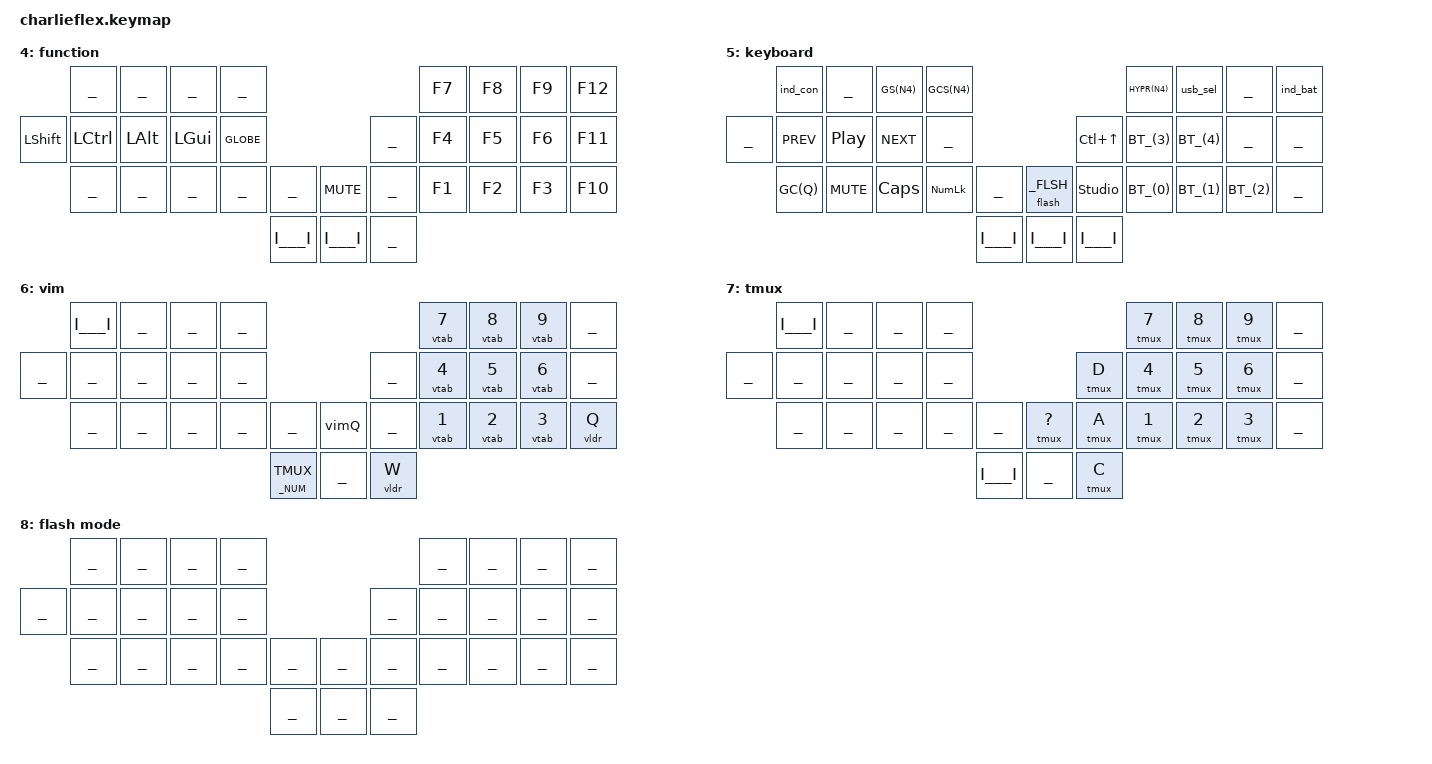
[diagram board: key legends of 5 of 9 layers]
#define ZMK_MOUSE_SCRL_VAL 140

#include <behaviors.dtsi>
#include <dt-bindings/zmk/bt.h>
#include <dt-bindings/zmk/keys.h>
#include <dt-bindings/zmk/outputs.h>
#include <dt-bindings/zmk/pointing.h>
#include <behaviors/rgbled_widget.dtsi>
#include "common.keys"

// Layers
#define _CLMK 0
#define _NUM 1
#define _NAV 2
#define _SYM 3
#define _FN 4
#define _KBD 5
#define _VIM 6
#define _TMUX 7
#define _FLSH 8

// Key positions for combos
// ┏━━━━┳━━━━┳━━━━┳━━━━┓                    ┏━━━━┳━━━━┳━━━━┳━━━━┓
// ┃ 0  ┃ 1  ┃ 2  ┃ 3  ┃                    ┃ 4  ┃ 5  ┃ 6  ┃ 7  ┃
// ┣━━━━╋━━━━╋━━━━╋━━━━╋━━━━┓          ┏━━━━╋━━━━╋━━━━╋━━━━╋━━━━┫
// ┃ 8  ┃ 9  ┃ 10 ┃<11>┃ 12 ┃          ┃ 13 ┃<14>┃ 15 ┃ 16 ┃ 17 ┃
// ┣━━━━╋━━━━╋━━━━╋━━━━╋━━━━┫  ┏━━━━┓  ┣━━━━╋━━━━╋━━━━╋━━━━╋━━━━┫
// ┃ 18 ┃ 19 ┃ 20 ┃ 21 ┃ 22 ┃  ┃ 23 ┃  ┃ 24 ┃ 25 ┃ 26 ┃ 27 ┃ 28 ┃
// ┗━━━━┻━━━━┻━━━━┻━━━━╋━━━━╋━━┻━┳┳━┻━━╋━━━━┻━━━━┻━━━━┻━━━━┻━━━━┛
//                     ┃ 29 ┃ 30 ┃┃ 31 ┃
//                     ┗━━━━┻━━━━┛┗━━━━┛

/ {
    combos {
        compatible = "zmk,combos";

        combo_unlock {
            key-positions = <0 7>;
            bindings = <&studio_unlock>;
            layers = <_CLMK>;
        };

        combo_b {
            key-positions = <3 12>;
            bindings = <&kp B>;
            layers = <_CLMK>;
        };

        combo_j {
            key-positions = <4 13>;
            bindings = <&kp J>;
            layers = <_CLMK>;
        };

        combo_esc {
            key-positions = <1 2 3>;
            bindings = <&kp ESC>;
            layers = <_CLMK>;
        };

        combo_esc_pinky {
            key-positions = <0 1>;
            bindings = <&kp ESC>;
            layers = <_CLMK>;
        };

        combo_backspace {
            key-positions = <4 5 6>;
            bindings = <&kp BSPC>;
            layers = <_CLMK _NUM _NAV>;
        };

        combo_backspace_pinky {
            key-positions = <6 7>;
            bindings = <&kp BSPC>;
            layers = <_CLMK _NUM>;
        };

        combo_tab {
            key-positions = <9 10 11>;
            bindings = <&kp TAB>;
            layers = <_CLMK>;
        };

        combo_tab_pinky {
            key-positions = <18 19>;
            bindings = <&kp TAB>;
            layers = <_CLMK>;
        };

        combo_return {
            key-positions = <14 15 16>;
            bindings = <&kp RET>;
            layers = <_CLMK _NUM _NAV>;
        };

        combo_return_pinky {
            key-positions = <27 28>;
            bindings = <&kp RET>;
            require-prior-idle-ms = <150>;
            layers = <_CLMK _NUM>;
        };

        combo_left_paren {
            key-positions = <2 3>;
            bindings = <&kp LPAR>;
            layers = <_CLMK>;
        };

        combo_right_paren {
            key-positions = <4 5>;
            bindings = <&kp RPAR>;
            require-prior-idle-ms = <150>;
            layers = <_CLMK>;
        };

        combo_left_curly {
            key-positions = <10 11>;
            bindings = <&kp LBRC>;
            require-prior-idle-ms = <150>;
            layers = <_CLMK>;
        };

        combo_right_curly {
            key-positions = <14 15>;
            bindings = <&kp RBRC>;
            require-prior-idle-ms = <150>;
            layers = <_CLMK>;
        };

        combo_left_bracket {
            key-positions = <20 21>;
            bindings = <&kp LBKT>;
            require-prior-idle-ms = <150>;
            layers = <_CLMK>;
        };

        combo_right_bracket {
            key-positions = <25 26>;
            bindings = <&kp RBKT>;
            require-prior-idle-ms = <150>;
            layers = <_CLMK>;
        };

        combo_less_than {
            key-positions = <11 22>;
            bindings = <&kp LT>;
            layers = <_CLMK>;
        };

        combo_greater_than {
            key-positions = <14 24>;
            bindings = <&kp GT>;
            require-prior-idle-ms = <150>;
            layers = <_CLMK>;
        };

        combo_mouse_click {
            key-positions = <12 22>;
            bindings = <&mkp LCLK>;
            layers = <_CLMK>;
        };

        combo_mouse_right_click {
            key-positions = <8 18>;
            bindings = <&mkp RCLK>;
            layers = <_CLMK>;
        };

        combo_mouse_up {
            key-positions = <5 15>;
            bindings = <&mmv MOVE_UP>;
            layers = <_CLMK>;
        };

        combo_mouse_down {
            key-positions = <15 26>;
            bindings = <&mmv MOVE_DOWN>;
            layers = <_CLMK>;
        };

        combo_mouse_left {
            key-positions = <4 14>;
            bindings = <&mmv MOVE_LEFT>;
            layers = <_CLMK>;
        };

        combo_mouse_right {
            key-positions = <6 16>;
            bindings = <&mmv MOVE_RIGHT>;
            layers = <_CLMK>;
        };

        combo_scroll_up {
            key-positions = <2 10>;
            bindings = <&msc SCRL_UP>;
            layers = <_CLMK>;
        };

        combo_scroll_down {
            key-positions = <10 20>;
            bindings = <&msc SCRL_DOWN>;
            layers = <_CLMK>;
        };

        combo_scroll_left {
            key-positions = <1 9>;
            bindings = <&msc SCRL_LEFT>;
            layers = <_CLMK>;
        };

        combo_scroll_right {
            key-positions = <3 11>;
            bindings = <&msc SCRL_RIGHT>;
            layers = <_CLMK>;
        };

        // Combos are always executed on the central, so if we have a dongle
        // without an easily accessible reset button, we can use a combo to
        // put the central into bootloder mode
        combo_flash {
            key-positions = <12 13>;
            bindings = <&flash _FLSH>;
            layers = <_KBD>;
        };
    };

    behaviors {
        hmcs: homerow_mod_comma_semi {
            compatible = "zmk,behavior-hold-tap";
            #binding-cells = <2>;
            tapping-term-ms = <300>;
            require-prior-idle-ms = <150>;
            quick-tap-ms = <0>;
            flavor = "tap-preferred";
            bindings = <&kp>, <&mcs>;
        };

        key_rotation: sensor_rotation_kp {
            compatible = "zmk,behavior-sensor-rotate-var";
            #sensor-binding-cells = <2>;
            bindings = <&kp>, <&kp>;
        };

        scroll_rotation: sensor_rotation_scroll {
            compatible = "zmk,behavior-sensor-rotate-var";
            #sensor-binding-cells = <2>;
            bindings = <&msc>, <&msc>;
            tap-ms = <200>;
        };
    };

    conditional_layers {
        compatible = "zmk,conditional-layers";
        fn_layer {
            if-layers = <_NUM _NAV>;
            then-layer = <_FN>;
        };
        kbd_layer {
            if-layers = <_NAV _SYM>;
            then-layer = <_KBD>;
        };
        tmux_layer {
            if-layers = <_NUM _VIM>;
            then-layer = <_TMUX>;
        };
    };

    keymap {
        compatible = "zmk,keymap";

        colemak {
//                       ┏━━━━━━━━━━━━━━━━━━━━━━━━━┓
            display-name = "Colemak"               ;
//                       ┗━━━━━━━━━━━━━━━━━━━━━━━━━┛
            bindings = <
// ┏━━━━━━━┳━━━━━━━┳━━━━━━━┳━━━━━━━┓                                    ┏━━━━━━━┳━━━━━━━┳━━━━━━━┳━━━━━━━┓
// ┃   Q   ┃   W   ┃   F   ┃   P   ┃                                    ┃   L   ┃   U   ┃   Y   ┃  ' "  ┃
&lt _VIM Q   &kp W   &kp F   &kp P                                        &kp L   &kp U   &kp Y  &kp SQT
// ┣━━━━━━━╋━━━━━━━╋━━━━━━━╋━━━━━━━╋━━━━━━━┓                    ┏━━━━━━━╋━━━━━━━╋━━━━━━━╋━━━━━━━╋━━━━━━━┫
// ┃   A   ┃   R   ┃   S   ┃   T   ┃   G   ┃                    ┃   M   ┃   N   ┃   E   ┃   I   ┃   O   ┃
     Sft A   Ctl R   Opt S   Cmd T   Glb G                        Glb M   Cmd N   Opt E   Ctl I   Sft O
// ┃ Shift ┃ Ctrl  ┃  Opt  ┃  Cmd  ┃ Globe ┃                    ┃ Globe ┃  Cmd  ┃  Opt  ┃ Ctrl  ┃ Shift ┃
// ┣━━━━━━━╋━━━━━━━╋━━━━━━━╋━━━━━━━╋━━━━━━━┫     ┏━━━━━━━━┓     ┣━━━━━━━╋━━━━━━━╋━━━━━━━╋━━━━━━━╋━━━━━━━┫
// ┃   Z   ┃   X   ┃   C   ┃   D   ┃   V   ┃     ┃  MUTE  ┃     ┃   K   ┃   H   ┃  , ;  ┃  . :  ┃  / \  ┃
     &kp Z   &kp X   Alt C   &kp D   &kp V       &kp C_MUTE       &kp K &kp H &hmcs RALT 0 &mdc    &msb
// ┃       ┃       ┃ R Alt ┃       ┃       ┃     ┗━━━━━━━━┛     ┃       ┃       ┃ R Alt ┃       ┃       ┃
// ┗━━━━━━━┻━━━━━━━┻━━━━━━━┻━━━━━━━╋━━━━━━━╋━━━━━━━┓    ┏━━━━━━━╋━━━━━━━┻━━━━━━━┻━━━━━━━┻━━━━━━━┻━━━━━━━┛
//                                 ┃   -   ┃ SHIFT ┃    ┃ SPACE ┃
                          &lt _NUM MINUS &lsscw _NAV 0 &lt _SYM SPC
//                                 ┃  num  ┃  nav  ┃    ┃  sym  ┃
//                                 ┗━━━━━━━┻━━━━━━━┛    ┗━━━━━━━┛
            >;

            sensor-bindings = <&key_rotation C_VOL_UP C_VOL_DN>;
        };

        num {
//                       ┏━━━━━━━━━━━━━━━━━━━━━━━━━┓
            display-name = "numpad"                ;
//                       ┗━━━━━━━━━━━━━━━━━━━━━━━━━┛
            bindings = <
// ┏━━━━━━━┳━━━━━━━┳━━━━━━━┳━━━━━━━┓                                    ┏━━━━━━━┳━━━━━━━┳━━━━━━━┳━━━━━━━┓
// ┃  Esc  ┃       ┃scrnsht┃scrn cp┃                                    ┃   7   ┃   8   ┃   9   ┃   -   ┃
&lt _VIM ESC  ___    GS(N4) GCS(N4)                                    &kp N7  &kp N8  &kp N9  &kp MINUS
// ┣━━━━━━━╋━━━━━━━╋━━━━━━━╋━━━━━━━╋━━━━━━━┓                    ┏━━━━━━━╋━━━━━━━╋━━━━━━━╋━━━━━━━╋━━━━━━━┫
// ┃ CtrlA ┃ Bkspc ┃ SPACE ┃  Tab  ┃ Enter ┃                    ┃   /   ┃   4   ┃   5   ┃   6   ┃   +   ┃
 &kp LC(A) Ctl BSPC Opt SPC Cmd TAB Glb RET                  &kp SLASH &kp N4  &kp N5  &kp N6   &kp PLUS
// ┃       ┃ Ctrl  ┃  Opt  ┃  Cmd  ┃ Globe ┃                    ┃       ┃       ┃       ┃       ┃       ┃
// ┣━━━━━━━╋━━━━━━━╋━━━━━━━╋━━━━━━━╋━━━━━━━┫     ┏━━━━━━━━┓     ┣━━━━━━━╋━━━━━━━╋━━━━━━━╋━━━━━━━╋━━━━━━━┫
// ┃ CtrlZ ┃ CtrlX ┃ CtrlC ┃ CtrlD ┃ CtrlV ┃     ┃  PLAY  ┃     ┃   *   ┃   1   ┃   2   ┃   3   ┃   =   ┃
&kp LC(Z) &kp LC(X) Alt LC(C) &kp LC(D) &kp LC(V) &kp C_PP    &kp STAR &kp N1  &kp N2  &kp N3  &kp EQUAL
// ┃       ┃       ┃ R Alt ┃       ┃       ┃     ┗━━━━━━━━┛     ┃       ┃       ┃       ┃       ┃       ┃
// ┗━━━━━━━┻━━━━━━━┻━━━━━━━┻━━━━━━━╋━━━━━━━╋━━━━━━━┓    ┏━━━━━━━╋━━━━━━━┻━━━━━━━┻━━━━━━━┻━━━━━━━┻━━━━━━━┛
//                                 ┃ ##### ┃       ┃    ┃   0   ┃
                                     I___I &mo _NAV      &kp N0
//                                 ┃  num  ┃ func  ┃    ┃       ┃
//                                 ┗━━━━━━━┻━━━━━━━┛    ┗━━━━━━━┛
            >;

            sensor-bindings = <&key_rotation C_PREV C_NEXT>;
        };

        nav {
//                       ┏━━━━━━━━━━━━━━━━━━━━━━━━━┓
            display-name = "navigation"            ;
//                       ┗━━━━━━━━━━━━━━━━━━━━━━━━━┛
            bindings = <
// ┏━━━━━━━┳━━━━━━━┳━━━━━━━┳━━━━━━━┓                                    ┏━━━━━━━┳━━━━━━━┳━━━━━━━┳━━━━━━━┓
// ┃  Esc  ┃       ┃scrnsht┃scrn cp┃                                    ┃       ┃  Esc  ┃  Del  ┃ Bkspc ┃
    &kp ESC   ___    GS(N4) GCS(N4)                                        ___   &kp ESC &kp DEL &kp BSPC
// ┣━━━━━━━╋━━━━━━━╋━━━━━━━╋━━━━━━━╋━━━━━━━┓                    ┏━━━━━━━╋━━━━━━━╋━━━━━━━╋━━━━━━━╋━━━━━━━┫
// ┃ Cmd A ┃ Bkspc ┃ SPACE ┃  Tab  ┃ Enter ┃                    ┃ Pg Up ┃ Left  ┃  Up   ┃ Right ┃ Enter ┃
 Sft LG(A) Ctl BSPC Opt SPC Cmd TAB Glb RET                    &kp PG_UP &kp LEFT &kp UP &kp RIGHT &kp RET
// ┃ Shift ┃ Ctrl  ┃  Opt  ┃  Cmd  ┃ Globe ┃                    ┃       ┃       ┃       ┃       ┃       ┃
// ┣━━━━━━━╋━━━━━━━╋━━━━━━━╋━━━━━━━╋━━━━━━━┫     ┏━━━━━━━━┓     ┣━━━━━━━╋━━━━━━━╋━━━━━━━╋━━━━━━━╋━━━━━━━┫
// ┃ Cmd Z ┃ Cmd X ┃ Cmd C ┃ Cmd D ┃ Cmd V ┃     ┃  PREV  ┃     ┃ Pg Dn ┃ Home  ┃ Down  ┃  End  ┃ SPACE ┃
&kp LG(Z) &kp LG(X) Alt LG(C) &kp LG(D) &kp LG(V) &kp C_PREV  &kp PG_DN &kp HOME &kp DOWN &kp END &kp SPC
// ┃       ┃       ┃ R Alt ┃       ┃       ┃     ┗━━━━━━━━┛     ┃       ┃       ┃       ┃       ┃       ┃
// ┗━━━━━━━┻━━━━━━━┻━━━━━━━┻━━━━━━━╋━━━━━━━╋━━━━━━━┓    ┏━━━━━━━╋━━━━━━━┻━━━━━━━┻━━━━━━━┻━━━━━━━┻━━━━━━━┛
//                                 ┃       ┃ ##### ┃    ┃  Tab  ┃
                                  &mo _NUM   I___I      &lt _SYM TAB
//                                 ┃ func  ┃       ┃    ┃ keybd ┃
//                                 ┗━━━━━━━┻━━━━━━━┛    ┗━━━━━━━┛
            >;

            sensor-bindings = <&scroll_rotation SCRL_UP SCRL_DOWN>;
        };

        sym {
//                       ┏━━━━━━━━━━━━━━━━━━━━━━━━━┓
            display-name = "symbols"               ;
//                       ┗━━━━━━━━━━━━━━━━━━━━━━━━━┛
            bindings = <
// ┏━━━━━━━┳━━━━━━━┳━━━━━━━┳━━━━━━━┓                                    ┏━━━━━━━┳━━━━━━━┳━━━━━━━┳━━━━━━━┓
// ┃   `   ┃   #   ┃   %   ┃   *   ┃                                    ┃ CtrlL ┃ CtrlU ┃  Del  ┃ Bkspc ┃
&kp GRAVE &kp HASH &kp PRCNT &kp STAR                                 &kp LC(L) &kp LC(U) &kp DEL &kp BSPC
// ┣━━━━━━━╋━━━━━━━╋━━━━━━━╋━━━━━━━╋━━━━━━━┓                    ┏━━━━━━━╋━━━━━━━╋━━━━━━━╋━━━━━━━╋━━━━━━━┫
// ┃   ^   ┃   @   ┃   !   ┃   =   ┃   $   ┃                    ┃ Pg Up ┃ Left  ┃  Up   ┃ Right ┃ Enter ┃
&kp CARET &kp AT &kp EXCL &kp EQUAL &kp DLLR                   Glb PG_UP Cmd LEFT Opt UP Ctl RIGHT &kp RET
// ┃       ┃       ┃       ┃       ┃       ┃                    ┃ Globe ┃  Cmd  ┃  Opt  ┃ Ctrl  ┃       ┃
// ┣━━━━━━━╋━━━━━━━╋━━━━━━━╋━━━━━━━╋━━━━━━━┫     ┏━━━━━━━━┓     ┣━━━━━━━╋━━━━━━━╋━━━━━━━╋━━━━━━━╋━━━━━━━┫
// ┃   ~   ┃   |   ┃   +   ┃   &   ┃   ?   ┃     ┃  NEXT  ┃     ┃ Pg Dn ┃ Home  ┃ Down  ┃  End  ┃ SPACE ┃
&kp TILDE &kp PIPE &kp PLUS &kp AMPS &kp QMARK   &kp C_NEXT   &kp PG_DN &kp HOME Alt DOWN &kp END &kp SPC
// ┃       ┃       ┃       ┃       ┃       ┃     ┗━━━━━━━━┛     ┃       ┃       ┃ R Alt ┃       ┃       ┃
// ┗━━━━━━━┻━━━━━━━┻━━━━━━━┻━━━━━━━╋━━━━━━━╋━━━━━━━┓    ┏━━━━━━━╋━━━━━━━┻━━━━━━━┻━━━━━━━┻━━━━━━━┻━━━━━━━┛
//                                 ┃   _   ┃   /   ┃    ┃ ##### ┃
                               &kp UNDER &lt _NAV SLASH   I___I
//                                 ┃       ┃ keybd ┃    ┃       ┃
//                                 ┗━━━━━━━┻━━━━━━━┛    ┗━━━━━━━┛
            >;

            sensor-bindings = <&scroll_rotation SCRL_UP SCRL_DOWN>;
        };

        fn {
//                       ┏━━━━━━━━━━━━━━━━━━━━━━━━━┓
            display-name = "function"              ;
//                       ┗━━━━━━━━━━━━━━━━━━━━━━━━━┛
            bindings = <
// ┏━━━━━━━┳━━━━━━━┳━━━━━━━┳━━━━━━━┓                                    ┏━━━━━━━┳━━━━━━━┳━━━━━━━┳━━━━━━━┓
// ┃       ┃       ┃       ┃       ┃                                    ┃  F7   ┃  F8   ┃  F9   ┃  F12  ┃
      ___     ___     ___     ___                                        &kp F7  &kp F8  &kp F9  &kp F12
// ┣━━━━━━━╋━━━━━━━╋━━━━━━━╋━━━━━━━╋━━━━━━━┓                    ┏━━━━━━━╋━━━━━━━╋━━━━━━━╋━━━━━━━╋━━━━━━━┫
// ┃       ┃       ┃       ┃       ┃       ┃                    ┃       ┃  F4   ┃  F5   ┃  F6   ┃  F11  ┃
&kp LSHFT &kp LCTRL &kp LALT &kp LGUI &kp GLOBE                    ___   &kp F4  &kp F5  &kp F6  &kp F11
// ┃ Shift ┃ Ctrl  ┃  Opt  ┃  Cmd  ┃ Globe ┃                    ┃       ┃       ┃       ┃       ┃       ┃
// ┣━━━━━━━╋━━━━━━━╋━━━━━━━╋━━━━━━━╋━━━━━━━┫     ┏━━━━━━━━┓     ┣━━━━━━━╋━━━━━━━╋━━━━━━━╋━━━━━━━╋━━━━━━━┫
// ┃       ┃       ┃       ┃       ┃       ┃     ┃  MUTE  ┃     ┃       ┃  F1   ┃  F2   ┃  F3   ┃  F10  ┃
      ___     ___     ___     ___     ___        &kp C_MUTE        ___   &kp F1   &kp F2 &kp F3  &kp F10
// ┃       ┃       ┃       ┃       ┃       ┃     ┗━━━━━━━━┛     ┃       ┃       ┃       ┃       ┃       ┃
// ┗━━━━━━━┻━━━━━━━┻━━━━━━━┻━━━━━━━╋━━━━━━━╋━━━━━━━┓    ┏━━━━━━━╋━━━━━━━┻━━━━━━━┻━━━━━━━┻━━━━━━━┻━━━━━━━┛
//                                 ┃ ##### ┃ ##### ┃    ┃       ┃
                                     I___I   I___I         ___
//                                 ┃       ┃       ┃    ┃       ┃
//                                 ┗━━━━━━━┻━━━━━━━┛    ┗━━━━━━━┛
            >;

            sensor-bindings = <&key_rotation C_BRI_UP C_BRI_DN>;
        };

        kbd {
//                       ┏━━━━━━━━━━━━━━━━━━━━━━━━━┓
            display-name = "keyboard"              ;
//                       ┗━━━━━━━━━━━━━━━━━━━━━━━━━┛
            bindings = <
// ┏━━━━━━━┳━━━━━━━┳━━━━━━━┳━━━━━━━┓                                    ┏━━━━━━━┳━━━━━━━┳━━━━━━━┳━━━━━━━┓
// ┃c stat ┃       ┃scrnsht┃scrn cp┃                                    ┃launchp┃  USB  ┃       ┃battery┃
   &ind_con   ___    GS(N4) GCS(N4)                                     HYPR(N4) &usb_sel  ___  &ind_bat
// ┣━━━━━━━╋━━━━━━━╋━━━━━━━╋━━━━━━━╋━━━━━━━┓                    ┏━━━━━━━╋━━━━━━━╋━━━━━━━╋━━━━━━━╋━━━━━━━┫
// ┃       ┃ prev  ┃ play  ┃ next  ┃       ┃                    ┃mission┃  BT4  ┃  BT5  ┃       ┃       ┃
    ___  &kp C_PREV &kp C_PP &kp C_NEXT  ___                   &kp LC(UP) BT_(3) BT_(4)    ___     ___
// ┃       ┃       ┃       ┃       ┃       ┃                    ┃control┃       ┃       ┃       ┃       ┃
// ┣━━━━━━━╋━━━━━━━╋━━━━━━━╋━━━━━━━╋━━━━━━━┫     ┏━━━━━━━━┓     ┣━━━━━━━╋━━━━━━━╋━━━━━━━╋━━━━━━━╋━━━━━━━┫
// ┃ lock  ┃ mute  ┃caps lk┃numlock┃       ┃     ┃ flash  ┃     ┃studio ┃  BT1  ┃  BT2  ┃  BT3  ┃       ┃
  GC(Q) &kp C_MUTE &kp CAPS &kp KP_NUM  ___   &flash _FLSH &studio_unlock BT_(0)  BT_(1)  BT_(2)   ___
// ┃       ┃       ┃       ┃       ┃       ┃     ┗━━━━━━━━┛     ┃ unlock┃       ┃       ┃       ┃       ┃
// ┗━━━━━━━┻━━━━━━━┻━━━━━━━┻━━━━━━━╋━━━━━━━╋━━━━━━━┓    ┏━━━━━━━╋━━━━━━━┻━━━━━━━┻━━━━━━━┻━━━━━━━┻━━━━━━━┛
//                                 ┃ ##### ┃ ##### ┃    ┃ ##### ┃
                                     I___I   I___I        I___I
//                                 ┃       ┃       ┃    ┃       ┃
//                                 ┗━━━━━━━┻━━━━━━━┛    ┗━━━━━━━┛
            >;

            sensor-bindings = <&key_rotation C_BRI_UP C_BRI_DN>;
        };

        vim {
//                       ┏━━━━━━━━━━━━━━━━━━━━━━━━━┓
            display-name = "vim"                   ;
//                       ┗━━━━━━━━━━━━━━━━━━━━━━━━━┛
            bindings = <
// ┏━━━━━━━┳━━━━━━━┳━━━━━━━┳━━━━━━━┓                                    ┏━━━━━━━┳━━━━━━━┳━━━━━━━┳━━━━━━━┓
// ┃ ##### ┃       ┃       ┃       ┃                                    ┃ tab 7 ┃ tab 8 ┃ tab 9 ┃       ┃
     I___I    ___     ___     ___                                      &vtab N7 &vtab N8 &vtab N9  ___
// ┣━━━━━━━╋━━━━━━━╋━━━━━━━╋━━━━━━━╋━━━━━━━┓                    ┏━━━━━━━╋━━━━━━━╋━━━━━━━╋━━━━━━━╋━━━━━━━┫
// ┃       ┃       ┃       ┃       ┃       ┃                    ┃       ┃ tab 4 ┃ tab 5 ┃ tab 6 ┃       ┃
      ___     ___     ___     ___     ___                          ___ &vtab N4 &vtab N5 &vtab N6  ___
// ┃       ┃       ┃       ┃       ┃       ┃                    ┃       ┃       ┃       ┃       ┃       ┃
// ┣━━━━━━━╋━━━━━━━╋━━━━━━━╋━━━━━━━╋━━━━━━━┫     ┏━━━━━━━━┓     ┣━━━━━━━╋━━━━━━━╋━━━━━━━╋━━━━━━━╋━━━━━━━┫
// ┃       ┃       ┃       ┃       ┃       ┃     ┃  QUIT  ┃     ┃       ┃ tab 1 ┃ tab 2 ┃ tab 3 ┃ exit  ┃
      ___     ___     ___     ___     ___          &vimQ           ___ &vtab N1 &vtab N2 &vtab N3 &vldr Q
// ┃       ┃       ┃       ┃       ┃       ┃     ┗━━━━━━━━┛     ┃       ┃       ┃       ┃       ┃       ┃
// ┗━━━━━━━┻━━━━━━━┻━━━━━━━┻━━━━━━━╋━━━━━━━╋━━━━━━━┓    ┏━━━━━━━╋━━━━━━━┻━━━━━━━┻━━━━━━━┻━━━━━━━┻━━━━━━━┛
//                                 ┃ tmux  ┃       ┃    ┃ save  ┃
                                &lt _NUM TMUX ___        &vldr W
//                                 ┃ leader┃       ┃    ┃       ┃
//                                 ┗━━━━━━━┻━━━━━━━┛    ┗━━━━━━━┛
            >;

            sensor-bindings = <&vim_tabs>;
        };

        tmux {
//                       ┏━━━━━━━━━━━━━━━━━━━━━━━━━┓
            display-name = "tmux"                  ;
//                       ┗━━━━━━━━━━━━━━━━━━━━━━━━━┛
            bindings = <
// ┏━━━━━━━┳━━━━━━━┳━━━━━━━┳━━━━━━━┓                                    ┏━━━━━━━┳━━━━━━━┳━━━━━━━┳━━━━━━━┓
// ┃ ##### ┃       ┃       ┃       ┃                                    ┃ tab 7 ┃ tab 8 ┃ tab 9 ┃       ┃
     I___I    ___     ___     ___                                      &tmux N7 &tmux N8 &tmux N9  ___
// ┣━━━━━━━╋━━━━━━━╋━━━━━━━╋━━━━━━━╋━━━━━━━┓                    ┏━━━━━━━╋━━━━━━━╋━━━━━━━╋━━━━━━━╋━━━━━━━┫
// ┃       ┃       ┃       ┃       ┃       ┃                    ┃ detach┃ tab 4 ┃ tab 5 ┃ tab 6 ┃       ┃
      ___     ___     ___     ___     ___                      &tmux D &tmux N4 &tmux N5 &tmux N6  ___
// ┃       ┃       ┃       ┃       ┃       ┃                    ┃       ┃       ┃       ┃       ┃       ┃
// ┣━━━━━━━╋━━━━━━━╋━━━━━━━╋━━━━━━━╋━━━━━━━┫     ┏━━━━━━━━┓     ┣━━━━━━━╋━━━━━━━╋━━━━━━━╋━━━━━━━╋━━━━━━━┫
// ┃       ┃       ┃       ┃       ┃       ┃     ┃  HELP  ┃     ┃ rename┃ tab 1 ┃ tab 2 ┃ tab 3 ┃       ┃
      ___     ___     ___     ___     ___       &tmux QMARK    &tmux A &tmux N1 &tmux N2 &tmux N3  ___
// ┃       ┃       ┃       ┃       ┃       ┃     ┗━━━━━━━━┛     ┃       ┃       ┃       ┃       ┃       ┃
// ┗━━━━━━━┻━━━━━━━┻━━━━━━━┻━━━━━━━╋━━━━━━━╋━━━━━━━┓    ┏━━━━━━━╋━━━━━━━┻━━━━━━━┻━━━━━━━┻━━━━━━━┻━━━━━━━┛
//                                 ┃ ##### ┃       ┃    ┃  new  ┃
                                     I___I    ___        &tmux C
//                                 ┃       ┃       ┃    ┃       ┃
//                                 ┗━━━━━━━┻━━━━━━━┛    ┗━━━━━━━┛
            >;

            sensor-bindings = <&tmux_tabs>;
        };

        flash {
//                       ┏━━━━━━━━━━━━━━━━━━━━━━━━━┓
            display-name = "flash mode"            ;
//                       ┗━━━━━━━━━━━━━━━━━━━━━━━━━┛
            bindings = <
// ┏━━━━━━━┳━━━━━━━┳━━━━━━━┳━━━━━━━┓                                    ┏━━━━━━━┳━━━━━━━┳━━━━━━━┳━━━━━━━┓
// ┃       ┃       ┃       ┃       ┃                                    ┃       ┃       ┃       ┃       ┃
      ___     ___     ___     ___                                          ___     ___     ___     ___
// ┣━━━━━━━╋━━━━━━━╋━━━━━━━╋━━━━━━━╋━━━━━━━┓                    ┏━━━━━━━╋━━━━━━━╋━━━━━━━╋━━━━━━━╋━━━━━━━┫
// ┃       ┃       ┃       ┃       ┃       ┃                    ┃       ┃       ┃       ┃       ┃       ┃
      ___     ___     ___     ___     ___                          ___     ___     ___     ___     ___
// ┃       ┃       ┃       ┃       ┃       ┃                    ┃       ┃       ┃       ┃       ┃       ┃
// ┣━━━━━━━╋━━━━━━━╋━━━━━━━╋━━━━━━━╋━━━━━━━┫     ┏━━━━━━━━┓     ┣━━━━━━━╋━━━━━━━╋━━━━━━━╋━━━━━━━╋━━━━━━━┫
// ┃       ┃       ┃       ┃       ┃       ┃     ┃        ┃     ┃       ┃       ┃       ┃       ┃       ┃
      ___     ___     ___     ___     ___           ___            ___     ___     ___     ___     ___
// ┃       ┃       ┃       ┃       ┃       ┃     ┗━━━━━━━━┛     ┃       ┃       ┃       ┃       ┃       ┃
// ┗━━━━━━━┻━━━━━━━┻━━━━━━━┻━━━━━━━╋━━━━━━━╋━━━━━━━┓    ┏━━━━━━━╋━━━━━━━┻━━━━━━━┻━━━━━━━┻━━━━━━━┻━━━━━━━┛
//                                 ┃       ┃       ┃    ┃       ┃
                                      ___     ___          ___
//                                 ┃       ┃       ┃    ┃       ┃
//                                 ┗━━━━━━━┻━━━━━━━┛    ┗━━━━━━━┛
            >;

            sensor-bindings = <&scroll_rotation SCRL_UP SCRL_DOWN>;
        };

        // Extra empty layers for ZMK Studio

        layer9 {
            status = "reserved";
        };

        layer10 {
            status = "reserved";
        };

        layer11 {
            status = "reserved";
        };

        layer12 {
            status = "reserved";
        };

        layer13 {
            status = "reserved";
        };

        layer14 {
            status = "reserved";
        };

        layer15 {
            status = "reserved";
        };
    };
};

// vim: expandtab softtabstop=4 shiftwidth=4 filetype=dts
